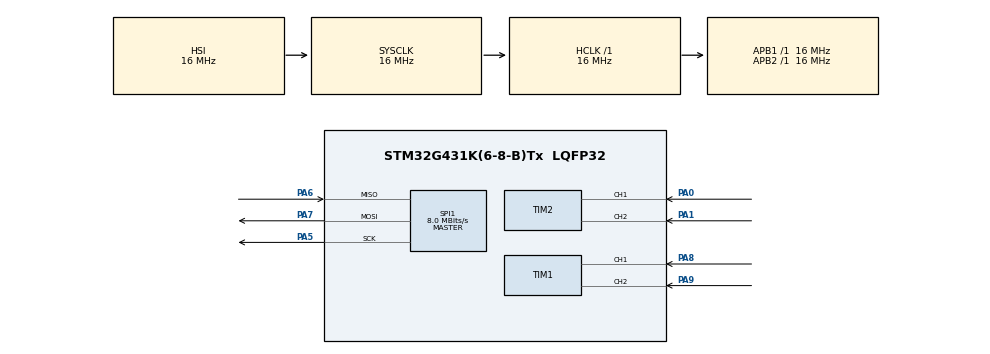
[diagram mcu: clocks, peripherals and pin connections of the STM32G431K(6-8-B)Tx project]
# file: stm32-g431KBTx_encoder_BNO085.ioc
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Mcu.Family=STM32G4
Mcu.Name=STM32G431K(6-8-B)Tx
Mcu.Package=LQFP32
NVIC.PriorityGroup=NVIC_PRIORITYGROUP_4
PA0.Signal=S_TIM2_CH1
PA1.Signal=S_TIM2_CH2
PA5.Mode=Full_Duplex_Master
PA5.Signal=SPI1_SCK
PA6.Mode=Full_Duplex_Master
PA6.Signal=SPI1_MISO
PA7.Mode=Full_Duplex_Master
PA7.Signal=SPI1_MOSI
PA8.Signal=S_TIM1_CH1
PA9.Signal=S_TIM1_CH2
ProjectManager.HeapSize=0x200
ProjectManager.StackSize=0x400
ProjectManager.TargetToolchain=CMake
RCC.AHBFreq_Value=16000000
RCC.APB1Freq_Value=16000000
RCC.APB1TimFreq_Value=16000000
RCC.APB2Freq_Value=16000000
RCC.APB2TimFreq_Value=16000000
RCC.CortexFreq_Value=16000000
RCC.EXTERNAL_CLOCK_VALUE=12288000
RCC.HCLKFreq_Value=16000000
RCC.HSE_VALUE=8000000
RCC.HSI48_VALUE=48000000
RCC.HSI_VALUE=16000000
RCC.LSE_VALUE=32768
RCC.SYSCLKFreq_VALUE=16000000
RCC.USBFreq_Value=64000000
RCC.VCOOutputFreq_Value=128000000
SH.S_TIM1_CH1.0=TIM1_CH1,Encoder_Interface
SH.S_TIM1_CH2.0=TIM1_CH2,Encoder_Interface
SH.S_TIM2_CH1.0=TIM2_CH1,Encoder_Interface
SH.S_TIM2_CH2.0=TIM2_CH2,Encoder_Interface
SPI1.CalculateBaudRate=8.0 MBits/s
SPI1.Direction=SPI_DIRECTION_2LINES
SPI1.Mode=SPI_MODE_MASTER
SPI1.VirtualType=VM_MASTER
VP_SYS_VS_DBSignals.Mode=DisableDeadBatterySignals
board=custom

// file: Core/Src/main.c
/* USER CODE BEGIN Header */
/**
  ******************************************************************************
  * @file           : main.c
  * @brief          : Main program body
  ******************************************************************************
  * @attention
  *
  * Copyright (c) 2026 STMicroelectronics.
  * All rights reserved.
  *
  * This software is licensed under terms that can be found in the LICENSE file
  * in the root directory of this software component.
  * If no LICENSE file comes with this software, it is provided AS-IS.
  *
  ******************************************************************************
  */
/* USER CODE END Header */
#include "main.h"

SPI_HandleTypeDef hspi1;

TIM_HandleTypeDef htim1;
TIM_HandleTypeDef htim2;

/* USER CODE BEGIN PV */
uint16_t pos1 = 0;
uint16_t pos2 = 0;
uint16_t prev1 = 0;
uint16_t prev2 = 0;
/* USER CODE END PV */

void SystemClock_Config(void);
static void MX_GPIO_Init(void);
static void MX_SPI1_Init(void);
static void MX_TIM1_Init(void);
static void MX_TIM2_Init(void);

int main(void)
{

  /* MCU Configuration--------------------------------------------------------*/

  /* Reset of all peripherals, Initializes the Flash interface and the Systick. */
  HAL_Init();

  /* Configure the system clock */
  SystemClock_Config();

  /* Initialize all configured peripherals */
  MX_GPIO_Init();
  MX_SPI1_Init();
  MX_TIM1_Init();
  MX_TIM2_Init();
  /* USER CODE BEGIN 2 */
  HAL_TIM_ENCODER_Start(&htim1, TIM_CHANNEL_ALL);
  HAL_TIM_ENCODER_Start(&htim2, TIM_CHANNEL_ALL);
  /* USER CODE END 2 */

  /* Infinite loop */
  while (1)
  {

  }
}

void SystemClock_Config(void)
{
  RCC_OscInitTypeDef RCC_OscInitStruct = {0};
  RCC_ClkInitTypeDef RCC_ClkInitStruct = {0};

  /** Configure the main internal regulator output voltage
  */
  HAL_PWREx_ControlVoltageScaling(PWR_REGULATOR_VOLTAGE_SCALE1);

  /** Initializes the RCC Oscillators according to the specified parameters
  * in the RCC_OscInitTypeDef structure.
  */
  RCC_OscInitStruct.OscillatorType = RCC_OSCILLATORTYPE_HSI;
  RCC_OscInitStruct.HSIState = RCC_HSI_ON;
  RCC_OscInitStruct.HSICalibrationValue = RCC_HSICALIBRATION_DEFAULT;
  RCC_OscInitStruct.PLL.PLLState = RCC_PLL_NONE;
  if (HAL_RCC_OscConfig(&RCC_OscInitStruct) != HAL_OK)
  {
    Error_Handler();
  }

  /** Initializes the CPU, AHB and APB buses clocks
  */
  RCC_ClkInitStruct.ClockType = RCC_CLOCKTYPE_HCLK|RCC_CLOCKTYPE_SYSCLK
                              |RCC_CLOCKTYPE_PCLK1|RCC_CLOCKTYPE_PCLK2;
  RCC_ClkInitStruct.SYSCLKSource = RCC_SYSCLKSOURCE_HSI;
  RCC_ClkInitStruct.AHBCLKDivider = RCC_SYSCLK_DIV1;
  RCC_ClkInitStruct.APB1CLKDivider = RCC_HCLK_DIV1;
  RCC_ClkInitStruct.APB2CLKDivider = RCC_HCLK_DIV1;

  if (HAL_RCC_ClockConfig(&RCC_ClkInitStruct, FLASH_LATENCY_0) != HAL_OK)
  {
    Error_Handler();
  }
}

static void MX_SPI1_Init(void)
{

  /* SPI1 parameter configuration*/
  hspi1.Instance = SPI1;
  hspi1.Init.Mode = SPI_MODE_MASTER;
  hspi1.Init.Direction = SPI_DIRECTION_2LINES;
  hspi1.Init.DataSize = SPI_DATASIZE_4BIT;
  hspi1.Init.CLKPolarity = SPI_POLARITY_LOW;
  hspi1.Init.CLKPhase = SPI_PHASE_1EDGE;
  hspi1.Init.NSS = SPI_NSS_SOFT;
  hspi1.Init.BaudRatePrescaler = SPI_BAUDRATEPRESCALER_2;
  hspi1.Init.FirstBit = SPI_FIRSTBIT_MSB;
  hspi1.Init.TIMode = SPI_TIMODE_DISABLE;
  hspi1.Init.CRCCalculation = SPI_CRCCALCULATION_DISABLE;
  hspi1.Init.CRCPolynomial = 7;
  hspi1.Init.CRCLength = SPI_CRC_LENGTH_DATASIZE;
  hspi1.Init.NSSPMode = SPI_NSS_PULSE_ENABLE;
  if (HAL_SPI_Init(&hspi1) != HAL_OK)
  {
    Error_Handler();
  }

}

static void MX_TIM1_Init(void)
{

  TIM_Encoder_InitTypeDef sConfig = {0};
  TIM_MasterConfigTypeDef sMasterConfig = {0};

  htim1.Instance = TIM1;
  htim1.Init.Prescaler = 0;
  htim1.Init.CounterMode = TIM_COUNTERMODE_UP;
  htim1.Init.Period = 65535;
  htim1.Init.ClockDivision = TIM_CLOCKDIVISION_DIV1;
  htim1.Init.RepetitionCounter = 0;
  htim1.Init.AutoReloadPreload = TIM_AUTORELOAD_PRELOAD_DISABLE;
  sConfig.EncoderMode = TIM_ENCODERMODE_TI1;
  sConfig.IC1Polarity = TIM_ICPOLARITY_RISING;
  sConfig.IC1Selection = TIM_ICSELECTION_DIRECTTI;
  sConfig.IC1Prescaler = TIM_ICPSC_DIV1;
  sConfig.IC1Filter = 0;
  sConfig.IC2Polarity = TIM_ICPOLARITY_RISING;
  sConfig.IC2Selection = TIM_ICSELECTION_DIRECTTI;
  sConfig.IC2Prescaler = TIM_ICPSC_DIV1;
  sConfig.IC2Filter = 0;
  if (HAL_TIM_Encoder_Init(&htim1, &sConfig) != HAL_OK)
  {
    Error_Handler();
  }
  sMasterConfig.MasterOutputTrigger = TIM_TRGO_RESET;
  sMasterConfig.MasterOutputTrigger2 = TIM_TRGO2_RESET;
  sMasterConfig.MasterSlaveMode = TIM_MASTERSLAVEMODE_DISABLE;
  if (HAL_TIMEx_MasterConfigSynchronization(&htim1, &sMasterConfig) != HAL_OK)
  {
    Error_Handler();
  }

}

static void MX_TIM2_Init(void)
{

  TIM_Encoder_InitTypeDef sConfig = {0};
  TIM_MasterConfigTypeDef sMasterConfig = {0};

  htim2.Instance = TIM2;
  htim2.Init.Prescaler = 0;
  htim2.Init.CounterMode = TIM_COUNTERMODE_UP;
  htim2.Init.Period = 4294967295;
  htim2.Init.ClockDivision = TIM_CLOCKDIVISION_DIV1;
  htim2.Init.AutoReloadPreload = TIM_AUTORELOAD_PRELOAD_DISABLE;
  sConfig.EncoderMode = TIM_ENCODERMODE_TI1;
  sConfig.IC1Polarity = TIM_ICPOLARITY_RISING;
  sConfig.IC1Selection = TIM_ICSELECTION_DIRECTTI;
  sConfig.IC1Prescaler = TIM_ICPSC_DIV1;
  sConfig.IC1Filter = 0;
  sConfig.IC2Polarity = TIM_ICPOLARITY_RISING;
  sConfig.IC2Selection = TIM_ICSELECTION_DIRECTTI;
  sConfig.IC2Prescaler = TIM_ICPSC_DIV1;
  sConfig.IC2Filter = 0;
  if (HAL_TIM_Encoder_Init(&htim2, &sConfig) != HAL_OK)
  {
    Error_Handler();
  }
  sMasterConfig.MasterOutputTrigger = TIM_TRGO_RESET;
  sMasterConfig.MasterSlaveMode = TIM_MASTERSLAVEMODE_DISABLE;
  if (HAL_TIMEx_MasterConfigSynchronization(&htim2, &sMasterConfig) != HAL_OK)
  {
    Error_Handler();
  }

}

static void MX_GPIO_Init(void)
{

  /* GPIO Ports Clock Enable */
  __HAL_RCC_GPIOA_CLK_ENABLE();

}

void Error_Handler(void)
{
  __disable_irq();
  while (1)
  {
  }
}
